# APM32F103xC register map
File version: 1.0
CPU: CM3 r2p1, little endian, no MPU, no FPU, 4 interrupt priority bits
Registers are 32-bit, read-write, reset 0x0 unless marked. A register's access mark holds for its fields unless they carry their own. Offsets are from the block's base; [hi:lo] are bit positions; {n}, {i} and the like mark numbered series.

## EINT — External Interrupt
Base 0x40010400
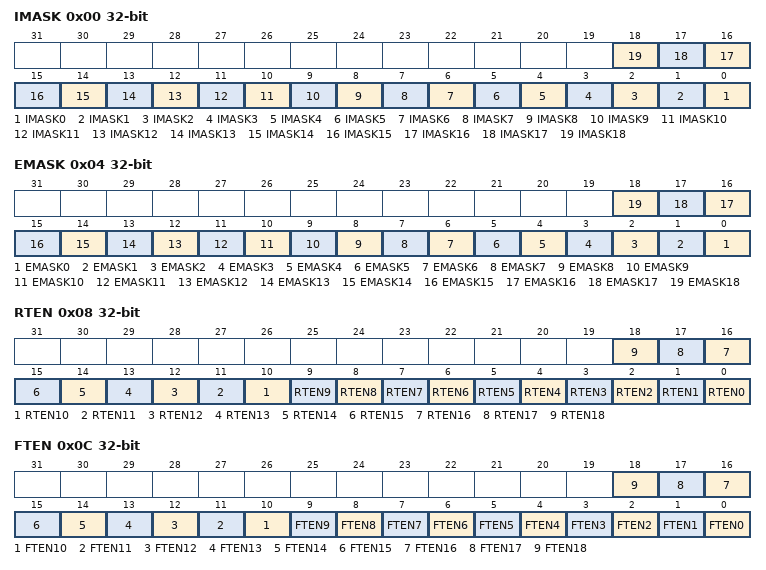
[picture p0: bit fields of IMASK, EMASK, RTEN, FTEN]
0x00 IMASK — Interrupt mask register (EINT_IMASK)
  [n] IMASK{n} (n=0..18) — Interrupt Mask on line {n}
0x04 EMASK — Event mask register (EINT_EMASK)
  [n] EMASK{n} (n=0..18) — Event Mask on line {n}
0x08 RTEN — Rising Trigger selection register (EINT_RTEN)
  [n] RTEN{n} (n=0..18) — Rising trigger event configuration of line {n}
0x0C FTEN — Falling Trigger selection register (EINT_FTEN)
  [n] FTEN{n} (n=0..18) — Falling trigger event configuration of line {n}
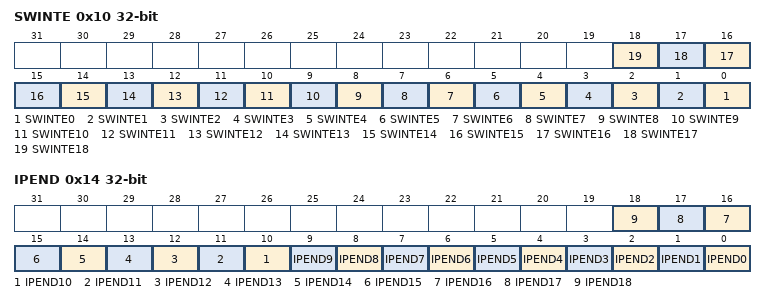
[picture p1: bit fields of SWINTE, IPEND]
0x10 SWINTE — Software interrupt event register (EINT_SWINTE)
  [n] SWINTE{n} (n=0..18) — Software Interrupt on line {n}
0x14 IPEND — Interrupt Flag Enable register (EINT_IPEND)
  [n] IPEND{n} (n=0..18) — Pending bit {n}

## AFIO — Alternate function I/O
Base 0x40010000
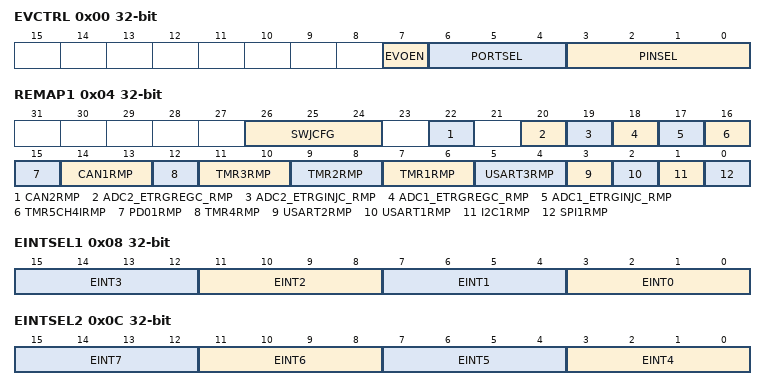
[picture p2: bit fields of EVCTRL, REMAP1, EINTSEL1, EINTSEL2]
0x00 EVCTRL — Event control register (AFIO_EVCTRL)
  [7] EVOEN, [6:4] PORTSEL, [3:0] PINSEL
0x04 REMAP1 access per field — Alternate function IO remap and Serial wire JTAG configuration register (AFIO_REMAP1)
  [26:24] SWJCFG wo — Serial wire JTAG configuration
  [22] CAN2RMP rw — CAN2 alternate function remapping
  [20] ADC2_ETRGREGC_RMP rw — ADC 2 external trigger regular conversion remapping
  [19] ADC2_ETRGINJC_RMP rw — ADC 2 external trigger injected conversion remapping
  [18] ADC1_ETRGREGC_RMP rw — ADC 1 external trigger regular conversion remapping
  [17] ADC1_ETRGINJC_RMP rw — ADC 1 External trigger injected conversion remapping
  [16] TMR5CH4IRMP rw — TMR5 channel4 internal remap
  [15] PD01RMP rw — Port D0/Port D1 mapping on OSC_IN/OSC_OUT
  [14:13] CAN1RMP rw — CAN1 alternate function remapping
  [12] TMR4RMP rw — TMR4 remapping
  [11:10] TMR3RMP rw — TMR3 remapping
  [9:8] TMR2RMP rw — TMR2 remapping
  [7:6] TMR1RMP rw — TMR1 remapping
  [5:4] USART3RMP rw — USART3 remapping
  [3] USART2RMP rw — USART2 remapping
  [2] USART1RMP rw — USART1 remapping
  [1] I2C1RMP rw — I2C1 remapping
  [0] SPI1RMP rw — SPI1 remapping
0x08 EINTSEL1 — External interrupt configuration register1 (AFIO_EINTSEL1)
  [4n+3:4n] EINT{n} (n=0..3) — EINT {n} configuration
0x0C EINTSEL2 — External interrupt configuration register2 (AFIO_EINTSEL2)
  [4n-13:4n-16] EINT{n} (n=4..7) — EINT {n} configuration
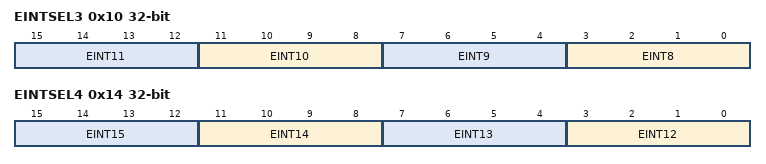
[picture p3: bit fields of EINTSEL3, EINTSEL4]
0x10 EINTSEL3 — External interrupt configuration register3 (AFIO_EINTSEL3)
  [4n-29:4n-32] EINT{n} (n=8..11) — EINT {n} configuration
0x14 EINTSEL4 — External interrupt configuration register4 (AFIO_EINTSEL4)
  [4n-45:4n-48] EINT{n} (n=12..15) — EINT {n} configuration
0x18 REMAP2 — Alternate function IO remap register2 (AFIO_REMAP2)
  [10] EMMCNADV — NAVD connect/disconnect

## PMU — Power control
Base 0x40007000
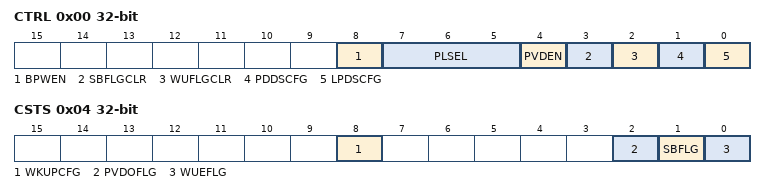
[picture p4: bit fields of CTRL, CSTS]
0x00 CTRL — Power control register (PMU_CTRL)
  [8] BPWEN — Disable Bakr Domain write protection
  [7:5] PLSEL — PVD Level Selection
  [4] PVDEN — Power Voltage Detector Enable
  [3] SBFLGCLR — Clear STANDBY Flag
  [2] WUFLGCLR — Clear Wake-up Flag
  [1] PDDSCFG — Power Down Deep Sleep
  [0] LPDSCFG — Low Power Deep Sleep
0x04 CSTS access per field — Power control/status register (PMU_CSTS)
  [8] WKUPCFG rw — Enable WKUP pin
  [2] PVDOFLG ro — PVD Output
  [1] SBFLG ro — STANDBY Flag
  [0] WUEFLG ro — Wake-Up Flag

## BAKPR — Bakr registers
Base 0x40006C00
{0x0+4i} DATA{i} (i=1..10) — Bakr data register (BAKPR_DATA)
  [15:0] DATA — Bakr data
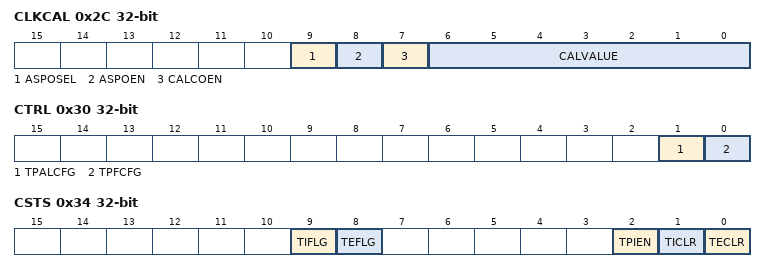
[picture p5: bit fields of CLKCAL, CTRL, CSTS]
0x2C CLKCAL — RTC clock calibration register (BAKPR_CLKCAL)
  [9] ASPOSEL — Alarm or second output selection
  [8] ASPOEN — Alarm or second output enable
  [7] CALCOEN — Calibration Clock Output
  [6:0] CALVALUE — Calibration value
0x30 CTRL — Bakr control register (BAKPR_CTRL)
  [1] TPALCFG — Tamper pin active level
  [0] TPFCFG — Tamper pin enable
0x34 CSTS access per field — Bakr control/status register (BAKPR_CSTS)
  [9] TIFLG ro — Tamper Interrupt Flag
  [8] TEFLG ro — Tamper Event Flag
  [2] TPIEN rw — Tamper Pin interrupt enable
  [1] TICLR wo — Clear Tamper Interrupt
  [0] TECLR wo — Clear Tamper event
{0x14+4i} DATA{i} (i=11..42) — Bakr data register (BAKPR_DATA)
  [15:0] DATA — Bakr data
